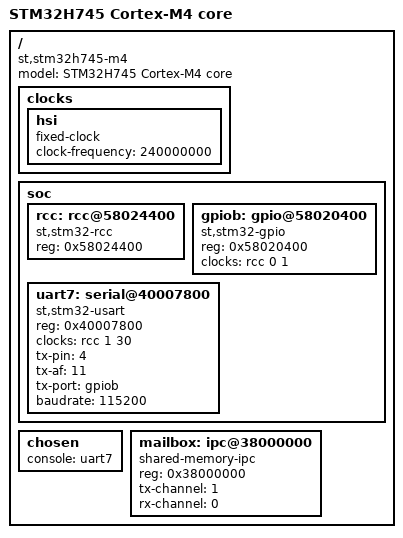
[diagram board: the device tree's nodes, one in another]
/ {
    compatible = "st,stm32h745-m4";
    model = "STM32H745 Cortex-M4 core";

    clocks {
        hsi: hsi {
            compatible = "fixed-clock";
            clock-frequency = <240000000>;  /* M4 runs at 240MHz */
        };
    };

    soc {
        rcc: rcc@58024400 {
            compatible = "st,stm32-rcc";
            reg = <0x58024400>;
        };

        gpiob: gpio@58020400 {
            compatible = "st,stm32-gpio";
            reg = <0x58020400>;
            clocks = <&rcc 0 1>;
        };

        uart7: serial@40007800 {
            compatible = "st,stm32-usart";
            reg = <0x40007800>;
            clocks = <&rcc 1 30>;
            tx-pin = <4>;
            tx-af = <11>;
            tx-port = <&gpiob>;
            baudrate = <115200>;
            status = "okay";
        };
    };

    chosen {
        console = <&uart7>;
    };

    mailbox: ipc@38000000 {
        compatible = "shared-memory-ipc";
        reg = <0x38000000>;
        tx-channel = <1>;   /* M4 sends on channel 1 */
        rx-channel = <0>;   /* M4 receives on channel 0 */
        status = "okay";
    };
};
